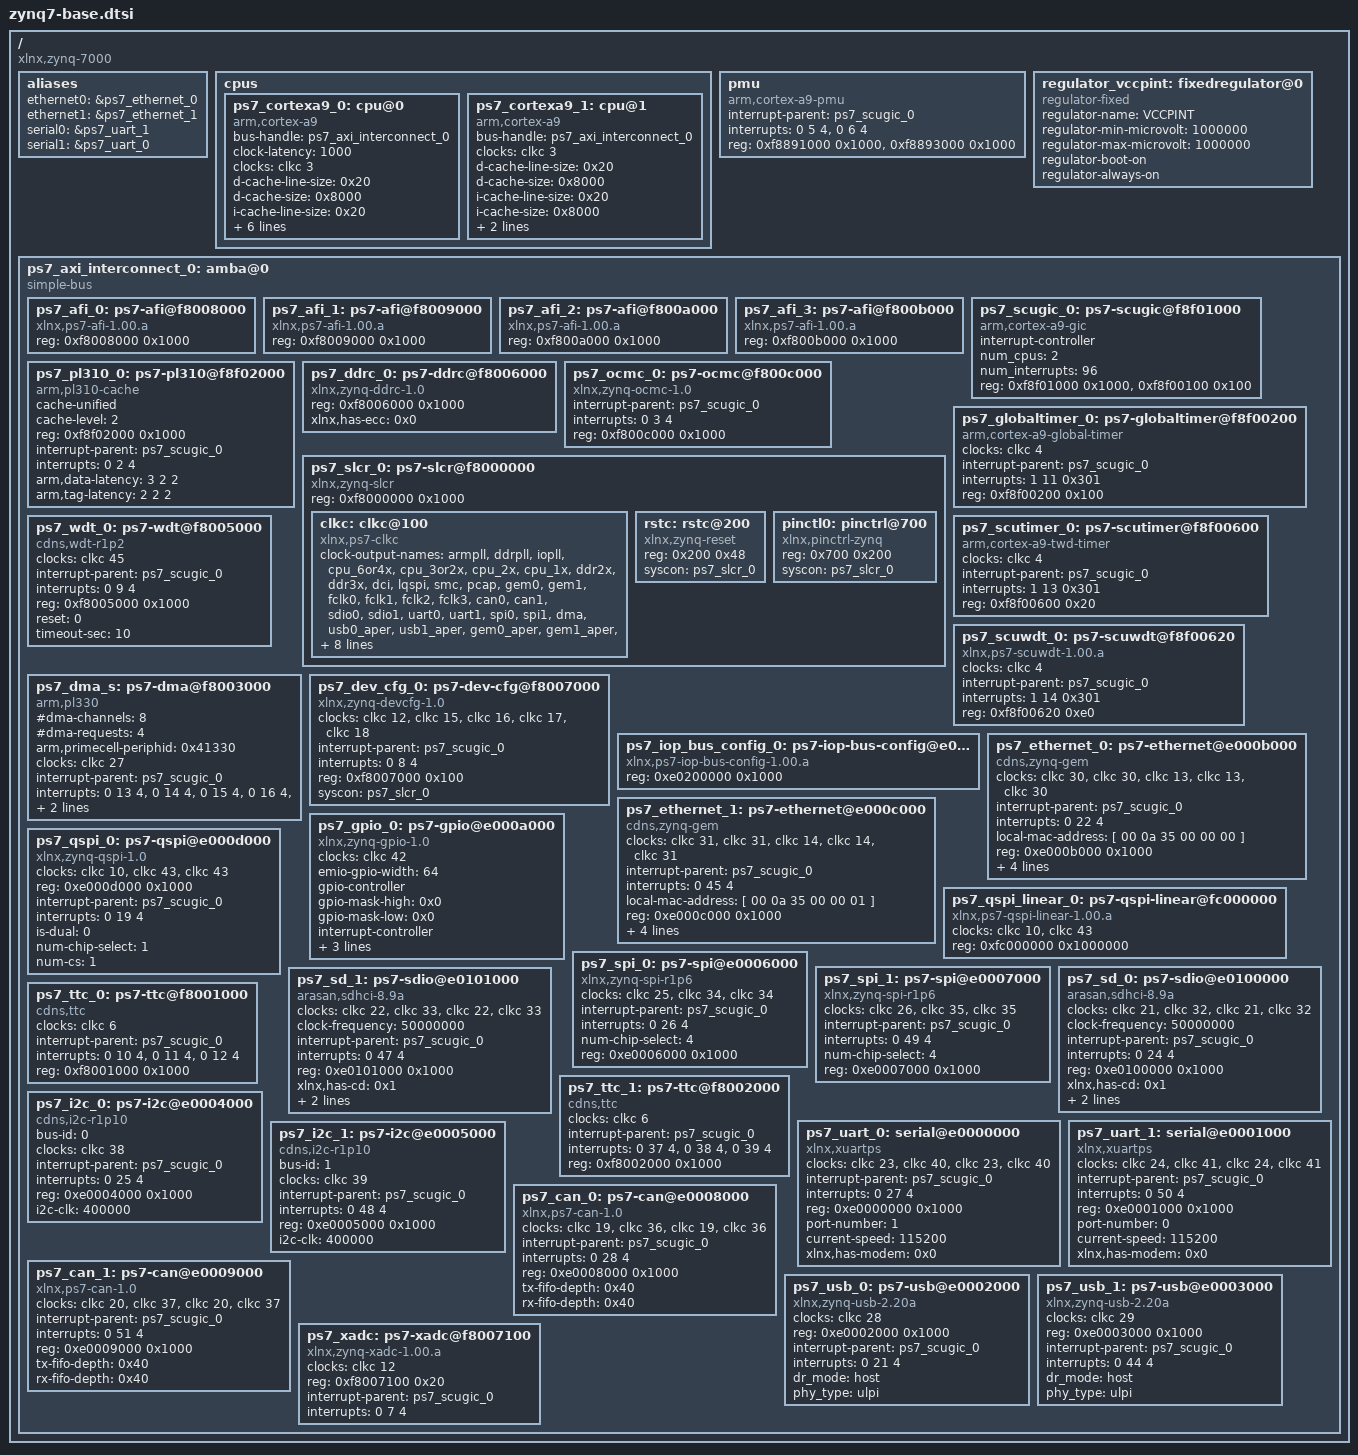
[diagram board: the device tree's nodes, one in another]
/*
 * Zynq 7000 Base Device Tree (System Peripherals and Configuration)
 *
 * To use this base include it in the dts/dtsi which relies on it.
 *     /dts-v1/;
 *     /include/ "zynq7-base.dtsi"
 *     / {
 *     ...
 *
 * In order to configure your board specific configuration of the Zynq platform,
 * or to configure additional devices attached to Zynq peripherals use the base
 * include and override properties, add subnodes or disable existing
 * peripherals.
 *
 * To disable or invalidate an existing Zynq peripheral:
 *     ...
 *         ps7_axi_interconnect_0: amba@0 {
 *             ps7_usb_1: ps7-usb@e0003000 { compatible = "invalid"; };
 *         } ;
 *     ...
 *
 * To override a property of an existing peripheral:
 *     ...
 *         ps7_axi_interconnect_0: amba@0 {
 *             ps7_usb_0: ps7-usb@e0002000 {
 *                 dr_mode = "device";
 *             } ;
 *         } ;
 *     ...
 *
 * To add an additional subnode (e.g. a device attached to a bus) to an existing
 * peripheral:
 *     ...
 *         ps7_axi_interconnect_0: amba@0 {
 *             ps7_ethernet_0: ps7-ethernet@e000b000 {
 *                 phy0: phy@7 {
 *                     device_type = "ethernet-phy";
 *                     reg = <7>;
 *                 } ;
 *             } ;
 *         } ;
 *     ...
 *
 * For more details, or for reference please refer to device trees in the
 * meta-xilinx layer that use this base tree.
 */

/ {
	#address-cells = <0x1>;
	#size-cells = <0x1>;
	compatible = "xlnx,zynq-7000";
	aliases {
		ethernet0 = &ps7_ethernet_0;
		ethernet1 = &ps7_ethernet_1;
		serial0 = &ps7_uart_1;
		serial1 = &ps7_uart_0;
	} ;
	cpus {
		#address-cells = <1>;
		#size-cells = <0>;
		ps7_cortexa9_0: cpu@0 {
			bus-handle = <&ps7_axi_interconnect_0>;
			clock-latency = <1000>;
			clocks = <&clkc 3>;
			compatible = "arm,cortex-a9";
			d-cache-line-size = <0x20>;
			d-cache-size = <0x8000>;
			device_type = "cpu";
			i-cache-line-size = <0x20>;
			i-cache-size = <0x8000>;
			interrupt-handle = <&ps7_scugic_0>;
			cpu0-supply = <&regulator_vccpint>;
			reg = <0x0>;
			operating-points = <
					666667 1000000
					333334 1000000
				>;
		} ;
		ps7_cortexa9_1: cpu@1 {
			bus-handle = <&ps7_axi_interconnect_0>;
			clocks = <&clkc 3>;
			compatible = "arm,cortex-a9";
			d-cache-line-size = <0x20>;
			d-cache-size = <0x8000>;
			device_type = "cpu";
			i-cache-line-size = <0x20>;
			i-cache-size = <0x8000>;
			interrupt-handle = <&ps7_scugic_0>;
			reg = <0x1>;
		} ;
	} ;
	pmu {
		compatible = "arm,cortex-a9-pmu";
		interrupt-parent = <&ps7_scugic_0>;
		interrupts = <0 5 4>, <0 6 4>;
		reg = <0xf8891000 0x1000>, <0xf8893000 0x1000>;
		reg-names = "cpu0", "cpu1";
	} ;
	regulator_vccpint: fixedregulator@0 {
		compatible = "regulator-fixed";
		regulator-name = "VCCPINT";
		regulator-min-microvolt = <1000000>;
		regulator-max-microvolt = <1000000>;
		regulator-boot-on;
		regulator-always-on;
	} ;
	ps7_axi_interconnect_0: amba@0 {
		#address-cells = <1>;
		#size-cells = <1>;
		compatible = "simple-bus", "xlnx,ps7-axi-interconnect-1.00.a";
		ranges ;
		ps7_afi_0: ps7-afi@f8008000 {
			compatible = "xlnx,ps7-afi-1.00.a";
			reg = <0xf8008000 0x1000>;
		} ;
		ps7_afi_1: ps7-afi@f8009000 {
			compatible = "xlnx,ps7-afi-1.00.a";
			reg = <0xf8009000 0x1000>;
		} ;
		ps7_afi_2: ps7-afi@f800a000 {
			compatible = "xlnx,ps7-afi-1.00.a";
			reg = <0xf800a000 0x1000>;
		} ;
		ps7_afi_3: ps7-afi@f800b000 {
			compatible = "xlnx,ps7-afi-1.00.a";
			reg = <0xf800b000 0x1000>;
		} ;
		ps7_scugic_0: ps7-scugic@f8f01000 {
			#address-cells = <2>;
			#interrupt-cells = <3>;
			#size-cells = <1>;
			compatible = "arm,cortex-a9-gic", "arm,gic", "xlnx,ps7-scugic-1.00.a";
			interrupt-controller ;
			num_cpus = <2>;
			num_interrupts = <96>;
			reg = <0xf8f01000 0x1000>, <0xf8f00100 0x100>;
		} ;
		ps7_pl310_0: ps7-pl310@f8f02000 {
			compatible = "arm,pl310-cache", "xlnx,ps7-pl310-1.00.a";
			cache-unified;
			cache-level = <2>;
			reg = <0xf8f02000 0x1000>;
			interrupt-parent = <&ps7_scugic_0>;
			interrupts = <0 2 4>;
			arm,data-latency = <3 2 2>;
			arm,tag-latency = <2 2 2>;
		} ;
		ps7_ddrc_0: ps7-ddrc@f8006000 {
			compatible = "xlnx,zynq-ddrc-1.0", "xlnx,ps7-ddrc-1.00.a", "xlnx,ps7-ddrc";
			reg = <0xf8006000 0x1000>;
			xlnx,has-ecc = <0x0>;
		} ;
		ps7_ocmc_0: ps7-ocmc@f800c000 {
			compatible = "xlnx,zynq-ocmc-1.0", "xlnx,ps7-ocm";
			interrupt-parent = <&ps7_scugic_0>;
			interrupts = <0 3 4>;
			reg = <0xf800c000 0x1000>;
		} ;
		ps7_slcr_0: ps7-slcr@f8000000 {
			#address-cells = <1>;
			#size-cells = <1>;
			compatible = "xlnx,zynq-slcr", "syscon", "simple-bus", "xlnx,ps7-slcr-1.00.a";
			ranges ;
			reg = <0xf8000000 0x1000>;
			clkc: clkc@100 {
				#clock-cells = <1>;
				clock-output-names = "armpll", "ddrpll", "iopll",
					"cpu_6or4x", "cpu_3or2x", "cpu_2x", "cpu_1x",
					"ddr2x", "ddr3x", "dci",
					"lqspi", "smc", "pcap",
					"gem0", "gem1",
					"fclk0", "fclk1", "fclk2", "fclk3",
					"can0", "can1",
					"sdio0", "sdio1",
					"uart0", "uart1",
					"spi0", "spi1",
					"dma",
					"usb0_aper", "usb1_aper",
					"gem0_aper", "gem1_aper",
					"sdio0_aper", "sdio1_aper",
					"spi0_aper", "spi1_aper",
					"can0_aper", "can1_aper",
					"i2c0_aper", "i2c1_aper",
					"uart0_aper", "uart1_aper",
					"gpio_aper", "lqspi_aper", "smc_aper", "swdt",
					"dbg_trc", "dbg_apb";
				compatible = "xlnx,ps7-clkc";
				fclk-enable = <0xf>;
				ps-clk-frequency = <33333333>;
				reg = <0x100 0x100>;
			} ;
			rstc: rstc@200 {
				compatible = "xlnx,zynq-reset";
				reg = <0x200 0x48>;
				#reset-cells = <1>;
				syscon = <&ps7_slcr_0>;
			} ;
			pinctl0: pinctrl@700 {
				compatible = "xlnx,pinctrl-zynq";
				reg = <0x700 0x200>;
				syscon = <&ps7_slcr_0>;
			} ;
		} ;
		ps7_globaltimer_0: ps7-globaltimer@f8f00200 {
			clocks = <&clkc 4>;
			compatible = "arm,cortex-a9-global-timer", "xlnx,ps7-globaltimer-1.00.a";
			interrupt-parent = <&ps7_scugic_0>;
			interrupts = <1 11 0x301>;
			reg = <0xf8f00200 0x100>;
		} ;
		ps7_scutimer_0: ps7-scutimer@f8f00600 {
			clocks = <&clkc 4>;
			compatible = "arm,cortex-a9-twd-timer", "xlnx,ps7-scutimer-1.00.a";
			interrupt-parent = <&ps7_scugic_0>;
			interrupts = <1 13 0x301>;
			reg = <0xf8f00600 0x20>;
		} ;
		ps7_scuwdt_0: ps7-scuwdt@f8f00620 {
			clocks = <&clkc 4>;
			compatible = "xlnx,ps7-scuwdt-1.00.a";
			device_type = "watchdog";
			interrupt-parent = <&ps7_scugic_0>;
			interrupts = <1 14 0x301>;
			reg = <0xf8f00620 0xe0>;
		} ;
		ps7_wdt_0: ps7-wdt@f8005000 {
			clocks = <&clkc 45>;
			compatible = "cdns,wdt-r1p2", "xlnx,zynq-wdt-r1p2";
			interrupt-parent = <&ps7_scugic_0>;
			interrupts = <0 9 4>;
			reg = <0xf8005000 0x1000>;
			reset = <0>;
			timeout-sec = <10>;
		} ;
		/*ps7_dma_ns: ps7-dma@f8004000 {
			#dma-cells = <1>;
			#dma-channels = <8>;
			#dma-requests = <4>;
			arm,primecell-periphid = <0x41330>;
			clock-names = "apb_pclk";
			clocks = <&clkc 27>;
			compatible = "arm,pl330", "arm,primecell", "xlnx,ps7-dma-1.00.a";
			interrupt-parent = <&ps7_scugic_0>;
			interrupt-names = "abort", "dma0", "dma1", "dma2", "dma3", "dma4", "dma5", "dma6", "dma7";
			interrupts = <0 13 4>, <0 14 4>, <0 15 4>, <0 16 4>, <0 17 4>, <0 40 4>, <0 41 4>, <0 42 4>, <0 43 4>;
			reg = <0xf8004000 0x1000>;
		} ;*/
		ps7_dma_s: ps7-dma@f8003000 {
			#dma-cells = <1>;
			#dma-channels = <8>;
			#dma-requests = <4>;
			arm,primecell-periphid = <0x41330>;
			clock-names = "apb_pclk";
			clocks = <&clkc 27>;
			compatible = "arm,pl330", "arm,primecell", "xlnx,ps7-dma-1.00.a";
			interrupt-parent = <&ps7_scugic_0>;
			interrupt-names = "abort", "dma0", "dma1", "dma2", "dma3", "dma4", "dma5", "dma6", "dma7";
			interrupts = <0 13 4>, <0 14 4>, <0 15 4>, <0 16 4>, <0 17 4>, <0 40 4>, <0 41 4>, <0 42 4>, <0 43 4>;
			reg = <0xf8003000 0x1000>;
		} ;
		ps7_dev_cfg_0: ps7-dev-cfg@f8007000 {
			clock-names = "ref_clk", "fclk0", "fclk1", "fclk2", "fclk3";
			clocks = <&clkc 12>, <&clkc 15>, <&clkc 16>, <&clkc 17>, <&clkc 18>;
			compatible = "xlnx,zynq-devcfg-1.0", "xlnx,ps7-dev-cfg-1.00.a";
			interrupt-parent = <&ps7_scugic_0>;
			interrupts = <0 8 4>;
			reg = <0xf8007000 0x100>;
			syscon = <&ps7_slcr_0>;
		} ;
		ps7_iop_bus_config_0: ps7-iop-bus-config@e0200000 {
			compatible = "xlnx,ps7-iop-bus-config-1.00.a";
			reg = <0xe0200000 0x1000>;
		} ;

		/* ========= Peripherals ========= */

		ps7_ethernet_0: ps7-ethernet@e000b000 {
			#address-cells = <1>;
			#size-cells = <0>;
			clock-names = "pclk", "hclk", "tx_clk", "ref_clk", "aper_clk";
			clocks = <&clkc 30>, <&clkc 30>, <&clkc 13>, <&clkc 13>, <&clkc 30>;
			compatible = "cdns,zynq-gem", "cdns,gem", "xlnx,ps7-ethernet-1.00.a";
			interrupt-parent = <&ps7_scugic_0>;
			interrupts = <0 22 4>;
			local-mac-address = [ 00 0a 35 00 00 00 ];
			reg = <0xe000b000 0x1000>;
			xlnx,enet-reset = <0xffffffff>;
			xlnx,eth-mode = <0x1>;
			xlnx,has-mdio = <0x1>;
			xlnx,ptp-enet-clock = <111111115>;
		} ;
		ps7_ethernet_1: ps7-ethernet@e000c000 {
			#address-cells = <1>;
			#size-cells = <0>;
			clock-names = "pclk", "hclk", "tx_clk", "ref_clk", "aper_clk";
			clocks = <&clkc 31>, <&clkc 31>, <&clkc 14>, <&clkc 14>, <&clkc 31>;
			compatible = "cdns,zynq-gem", "cdns,gem", "xlnx,ps7-ethernet-1.00.a";
			interrupt-parent = <&ps7_scugic_0>;
			interrupts = <0 45 4>;
			local-mac-address = [ 00 0a 35 00 00 01 ];
			reg = <0xe000c000 0x1000>;
			xlnx,enet-reset = <0xffffffff>;
			xlnx,eth-mode = <0x1>;
			xlnx,has-mdio = <0x1>;
			xlnx,ptp-enet-clock = <111111115>;
		} ;

		ps7_gpio_0: ps7-gpio@e000a000 {
			#gpio-cells = <2>;
			#interrupt-cells = <2>;
			clocks = <&clkc 42>;
			compatible = "xlnx,zynq-gpio-1.0", "xlnx,ps7-gpio-1.00.a";
			emio-gpio-width = <64>;
			gpio-controller ;
			gpio-mask-high = <0x0>;
			gpio-mask-low = <0x0>;
			interrupt-controller;
			interrupt-parent = <&ps7_scugic_0>;
			interrupts = <0 20 4>;
			reg = <0xe000a000 0x1000>;
		} ;

		ps7_qspi_0: ps7-qspi@e000d000 {
			clock-names = "ref_clk", "pclk", "aper_clk";
			clocks = <&clkc 10>, <&clkc 43>, <&clkc 43>;
			compatible = "xlnx,zynq-qspi-1.0", "xlnx,ps7-qspi-1.00.a";
			reg = <0xe000d000 0x1000>;
			interrupt-parent = <&ps7_scugic_0>;
			interrupts = <0 19 4>;
			is-dual = <0>;
			num-chip-select = <1>;
			num-cs = <1>;
			#address-cells = <1>;
			#size-cells = <0>;
		} ;
		ps7_qspi_linear_0: ps7-qspi-linear@fc000000 {
			clock-names = "ref_clk", "aper_clk";
			clocks = <&clkc 10>, <&clkc 43>;
			compatible = "xlnx,ps7-qspi-linear-1.00.a";
			reg = <0xfc000000 0x1000000>;
		} ;

		ps7_spi_0: ps7-spi@e0006000 {
			clock-names = "ref_clk", "pclk", "aper_clk";
			clocks = <&clkc 25>, <&clkc 34>, <&clkc 34>;
			compatible = "xlnx,zynq-spi-r1p6", "xlnx,ps7-spi-1.00.a";
			interrupt-parent = <&ps7_scugic_0>;
			interrupts = <0 26 4>;
			num-chip-select = <4>;
			reg = <0xe0006000 0x1000>;
			#address-cells = <1>;
			#size-cells = <0>;
		} ;
		ps7_spi_1: ps7-spi@e0007000 {
			clock-names = "ref_clk", "pclk", "aper_clk";
			clocks = <&clkc 26>, <&clkc 35>, <&clkc 35>;
			compatible = "xlnx,zynq-spi-r1p6", "xlnx,ps7-spi-1.00.a";
			interrupt-parent = <&ps7_scugic_0>;
			interrupts = <0 49 4>;
			num-chip-select = <4>;
			reg = <0xe0007000 0x1000>;
			#address-cells = <1>;
			#size-cells = <0>;
		} ;

		ps7_sd_0: ps7-sdio@e0100000 {
			clock-names = "clk_xin", "clk_ahb", "ref_clk", "aper_clk";
			clocks = <&clkc 21>, <&clkc 32>, <&clkc 21>, <&clkc 32>;
			clock-frequency = <50000000>;
			compatible = "arasan,sdhci-8.9a", "arasan,sdhci", "generic-sdhci", "xlnx,ps7-sdio-1.00.a";
			interrupt-parent = <&ps7_scugic_0>;
			interrupts = <0 24 4>;
			reg = <0xe0100000 0x1000>;
			xlnx,has-cd = <0x1>;
			xlnx,has-power = <0x0>;
			xlnx,has-wp = <0x1>;
		} ;
		ps7_sd_1: ps7-sdio@e0101000 {
			clock-names = "clk_xin", "clk_ahb", "ref_clk", "aper_clk";
			clocks = <&clkc 22>, <&clkc 33>, <&clkc 22>, <&clkc 33>;
			clock-frequency = <50000000>;
			compatible = "arasan,sdhci-8.9a", "arasan,sdhci", "generic-sdhci", "xlnx,ps7-sdio-1.00.a";
			interrupt-parent = <&ps7_scugic_0>;
			interrupts = <0 47 4>;
			reg = <0xe0101000 0x1000>;
			xlnx,has-cd = <0x1>;
			xlnx,has-power = <0x0>;
			xlnx,has-wp = <0x1>;
		} ;

		ps7_ttc_0: ps7-ttc@f8001000 {
			clocks = <&clkc 6>;
			compatible = "cdns,ttc", "xlnx,ps7-ttc-1.00.a";
			interrupt-names = "ttc0", "ttc1", "ttc2";
			interrupt-parent = <&ps7_scugic_0>;
			interrupts = <0 10 4>, <0 11 4>, <0 12 4>;
			reg = <0xf8001000 0x1000>;
		} ;
		ps7_ttc_1: ps7-ttc@f8002000 {
			clocks = <&clkc 6>;
			compatible = "cdns,ttc", "xlnx,ps7-ttc-1.00.a";
			interrupt-names = "ttc0", "ttc1", "ttc2";
			interrupt-parent = <&ps7_scugic_0>;
			interrupts = <0 37 4>, <0 38 4>, <0 39 4>;
			reg = <0xf8002000 0x1000>;
		} ;

		ps7_uart_0: serial@e0000000 {
			clock-names = "uart_clk", "pclk", "ref_clk", "aper_clk";
			clocks = <&clkc 23>, <&clkc 40>, <&clkc 23>, <&clkc 40>;
			compatible = "xlnx,xuartps", "cdns,uart-r1p8", "xlnx,ps7-uart-1.00.a";
			device_type = "serial";
			interrupt-parent = <&ps7_scugic_0>;
			interrupts = <0 27 4>;
			reg = <0xe0000000 0x1000>;
			port-number = <1>;
			current-speed = <115200>;
			xlnx,has-modem = <0x0>;
		} ;
		ps7_uart_1: serial@e0001000 {
			clock-names = "uart_clk", "pclk", "ref_clk", "aper_clk";
			clocks = <&clkc 24>, <&clkc 41>, <&clkc 24>, <&clkc 41>;
			compatible = "xlnx,xuartps", "cdns,uart-r1p8", "xlnx,ps7-uart-1.00.a";
			device_type = "serial";
			interrupt-parent = <&ps7_scugic_0>;
			interrupts = <0 50 4>;
			reg = <0xe0001000 0x1000>;
			port-number = <0>;
			current-speed = <115200>;
			xlnx,has-modem = <0x0>;
		} ;

		ps7_i2c_0: ps7-i2c@e0004000 {
			bus-id = <0>;
			clocks = <&clkc 38>;
			compatible = "cdns,i2c-r1p10", "xlnx,ps7-i2c-1.00.a";
			interrupt-parent = <&ps7_scugic_0>;
			interrupts = <0 25 4>;
			reg = <0xe0004000 0x1000>;
			i2c-clk = <400000>;
			#address-cells = <1>;
			#size-cells = <0>;
		} ;
		ps7_i2c_1: ps7-i2c@e0005000 {
			bus-id = <1>;
			clocks = <&clkc 39>;
			compatible = "cdns,i2c-r1p10", "xlnx,ps7-i2c-1.00.a";
			interrupt-parent = <&ps7_scugic_0>;
			interrupts = <0 48 4>;
			reg = <0xe0005000 0x1000>;
			i2c-clk = <400000>;
			#address-cells = <1>;
			#size-cells = <0>;
		} ;

		ps7_can_0: ps7-can@e0008000 {
			clock-names = "can_clk", "pclk", "ref_clk", "aper_clk";
			clocks = <&clkc 19>, <&clkc 36>, <&clkc 19>, <&clkc 36>;
			compatible = "xlnx,ps7-can-1.0", "xlnx,ps7-can", "xlnx,ps7-can-1.00.a";
			interrupt-parent = <&ps7_scugic_0>;
			interrupts = <0 28 4>;
			reg = <0xe0008000 0x1000>;
			tx-fifo-depth = <0x40>;
			rx-fifo-depth = <0x40>;
		} ;
		ps7_can_1: ps7-can@e0009000 {
			clock-names = "can_clk", "pclk", "ref_clk", "aper_clk";
			clocks = <&clkc 20>, <&clkc 37>, <&clkc 20>, <&clkc 37>;
			compatible = "xlnx,ps7-can-1.0", "xlnx,ps7-can", "xlnx,ps7-can-1.00.a";
			interrupt-parent = <&ps7_scugic_0>;
			interrupts = <0 51 4>;
			reg = <0xe0009000 0x1000>;
			tx-fifo-depth = <0x40>;
			rx-fifo-depth = <0x40>;
		} ;

		ps7_usb_0: ps7-usb@e0002000 {
			clocks = <&clkc 28>;
			compatible = "xlnx,zynq-usb-2.20a", "chipidea,usb2", "xlnx,ps7-usb-1.00.a", "xlnx,zynq-usb-1.00.a";
			reg = <0xe0002000 0x1000>;
			interrupt-parent = <&ps7_scugic_0>;
			interrupts = <0 21 4>;
			dr_mode = "host";
			phy_type = "ulpi";
		} ;
		ps7_usb_1: ps7-usb@e0003000 {
			clocks = <&clkc 29>;
			compatible = "xlnx,zynq-usb-2.20a", "chipidea,usb2", "xlnx,ps7-usb-1.00.a", "xlnx,zynq-usb-1.00.a";
			reg = <0xe0003000 0x1000>;
			interrupt-parent = <&ps7_scugic_0>;
			interrupts = <0 44 4>;
			dr_mode = "host";
			phy_type = "ulpi";
		} ;

		ps7_xadc: ps7-xadc@f8007100 {
			clocks = <&clkc 12>;
			compatible = "xlnx,zynq-xadc-1.00.a", "xlnx,ps7-xadc-1.00.a";
			reg = <0xf8007100 0x20>;
			interrupt-parent = <&ps7_scugic_0>;
			interrupts = <0 7 4>;
		} ;
	} ;
} ;
